# ATtiny20 device description
Architecture: AVR8L; Family: tinyAVR
Programming and debug interfaces: TPI
Registers are 8-bit, access not given, no defined reset value unless marked. A register's access mark holds for its fields unless they carry their own. Offsets are from the block's base; lines under a group give offsets from that group; [hi:lo] are bit positions; {n}, {i} and the like mark numbered series; 'fields as' and 'values as' point back to an identical list; <NAME> marks a mode.

## Ordering variants
ATtiny20-UUR: WLCSP12, pinout WLCSP, up to 12 MHz, -40 to 85 C, 1.8 to 5.5 V
ATtiny20-SSU: SOIC14, pinout DIP, up to 12 MHz, -40 to 85 C, 1.8 to 5.5 V
ATtiny20-XU: TSSOP14, pinout DIP, up to 12 MHz, -40 to 85 C, 1.8 to 5.5 V
ATtiny20-CCU: UFBGA15, pinout UFBGA, up to 12 MHz, -40 to 85 C, 1.8 to 5.5 V
ATtiny20-MMH: VQFN20, pinout VQFN, up to 12 MHz, -40 to 85 C, 1.8 to 5.5 V

## Memory
prog space: start 0x0000 size 0x0800, little endian
  0x0000 FLASH size 0x0800 flash, rw, executable, page 0x80
signatures space: start 0 size 3, little endian
  0 SIGNATURES size 3 signatures, ro
fuses space: start 0 size 0x0001, little endian
  0 FUSES size 0x0001 fuses, rw
lockbits space: start 0 size 0x0001, little endian
  0 LOCKBITS size 0x0001 lockbits, rw
data space: start 0x0000 size 0x4800, little endian
  0x0000 IO size 0x40 io
  0x0040 SRAM size 0x80 ram
  0x3F00 MAPPED_NVM_LOCK_BITS size 0x0002 sysreg
  0x3F40 MAPPED_CONFIGURATION_BITS size 0x0002 sysreg
  0x3F80 MAPPED_CALIBRATION_BITS size 0x0002 sysreg
  0x3FC0 MAPPED_DEVICE_ID_BITS size 0x0004 sysreg
  0x4000 MAPPED_FLASH size 0x0800 flash
osccal space: start 0 size 1, little endian
  0 OSCCAL size 1 osccal, ro

## Peripheral instances (address, pins/pin function, parameters)
PORTB at 0x00 — I/O Port
  pins: P0 PB0; P1 PB1; P2 PB2; P3 PB3
PORTA at 0x00 — I/O Port
  pins: P{n} PA{n} (n=0..7)
WDT at 0x00 — Watchdog Timer
ADC at 0x00 — Analog-to-Digital Converter
  pins: ADC{n} PA{n} (n=0..7)
AC at 0x00 — Analog Comparator
  pins: AIN0 PA1; AIN1 PA2
CPU at 0x00 — CPU Registers
  parameters: CORE_VERSION=AVR8L_0
EXINT at 0x00 — External Interrupts
  pins: PCINT{n} PA{n} (n=0..7); PCINT8 PB0; PCINT9 PB1; PCINT10 PB2; PCINT11 PB3; INT0 PB2
TC0 at 0x00 — Timer/Counter, 8-bit
  pins: OCB PA7; OCA PB2; T PB0
TWI at 0x00 — Two Wire Serial Interface
  pins: SCL PA7; SDA PB1
TC1 at 0x00 — Timer/Counter, 16-bit
  pins: OCA PB1; OCB PB2; ICP PA7; T PA7
SPI at 0x00 — Serial Peripheral Interface
  pins: SS PA6; MOSI PB1; MISO PB2; SCK PA7
FUSE at 0 in fuses — Fuses
LOCKBIT at 0 in lockbits — Lockbits

## Interrupts
0 RESET — External Reset, Power-on Reset and Watchdog Reset
1 INT0 — External Interrupt Request 0
2 PCINT0 — Pin Change Interrupt Request 0
3 PCINT1 — Pin Change Interrupt Request 1
4 WDT — Watchdog Time-out
5 TIM1_CAPT — Timer/Counter1 Input Capture
6 TIM1_COMPA — Timer/Counter1 Compare Match A
7 TIM1_COMPB — Timer/Counter1 Compare Match B
8 TIM1_OVF — Timer/Counter1 Overflow
9 TIM0_COMPA — Timer/Counter0 Compare Match A
10 TIM0_COMPB — Timer/Counter0 Compare Match B
11 TIM0_OVF — Timer/Counter0 Overflow
12 ANA_COMP — Analog Comparator
13 ADC_ADC — Conversion Complete
14 TWI_SLAVE — Two-Wire Interface
15 SPI — Serial Peripheral Interface
16 QTRIP — Touch Sensing

## Properties
SIGNATURES: SIGNATURE0=0x1e, SIGNATURE1=0x91, SIGNATURE2=0x0f

## Pinouts (pin number, pad)
DIP: 1 VCC, 2 PB0, 3 PB1, 4 PB3, 5 PB2, 6 PA7, 7 PA6, 8 PA5, 9 PA4, 10 PA3, 11 PA2, 12 PA1, 13 PA0, 14 GND
VQFN: 1 PA4, 2 PA3, 3 PA2, 4 PA1, 5 PA0, 8 GND, 9 VCC, 11 PB0, 12 PB1, 13 PB3, 14 PB2, 15 PA7, 16 PA6, 17 PA5
UFBGA: B1 PA4, C1 PA3, D1 PA0, A2 PA5, B2 PA7, C2 PA2, D2 GND, A3 PA6, B3 PB1, C3 PA1, D3 GND, A4 PB2, B4 PB3, C4 PB0, D4 VCC
WLCSP: A1 PA4, A3 PA1, A5 PA2, B2 PA6, B4 GND, B6 VDD, C1 PA5, C3 PA7, C5 PB1, D2 PB2, D4 PB3, D6 PB0

## FUSE — Fuses
Instances: FUSE 0 in fuses
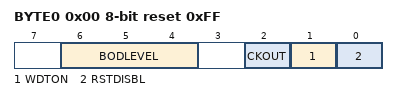
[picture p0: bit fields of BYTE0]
0x00 BYTE0 reset 0xFF
  [6:4] BODLEVEL — Brown-out Detector trigger level
    7=DISABLED (Brown-out detection disabled; [BODLEVEL=111]); 6=1V8 (Brown-out detection at VCC=1.8 V); 5=2V7 (Brown-out detection at VCC=2.7 V); 4=4V3 (Brown-out detection at VCC=4.3 V)
  [2] CKOUT — Output external clock
  [1] WDTON — Watch dog timer always on
  [0] RSTDISBL — Disable external reset
